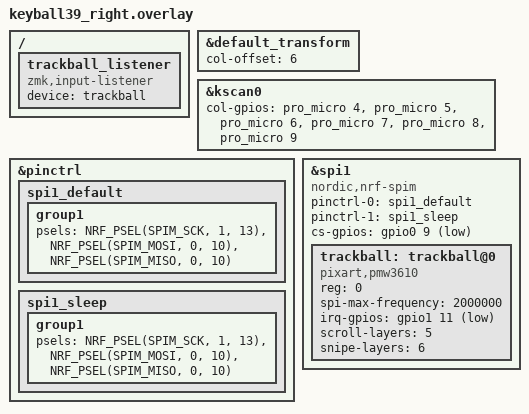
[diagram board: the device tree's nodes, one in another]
/*
 * Copyright (c) 2020 ZMK Contributors
 *
 * SPDX-License-Identifier: MIT
 */

#include "keyball39.dtsi"

&default_transform {
    col-offset = <6>;
};

&kscan0 {
	col-gpios
		= <&pro_micro 4 GPIO_ACTIVE_HIGH>
		, <&pro_micro 5 GPIO_ACTIVE_HIGH>
		, <&pro_micro 6 GPIO_ACTIVE_HIGH>
		, <&pro_micro 7 GPIO_ACTIVE_HIGH>
		, <&pro_micro 8 GPIO_ACTIVE_HIGH>
        , <&pro_micro 9 GPIO_ACTIVE_HIGH>
		;
};

&pinctrl {
    spi1_default: spi1_default {
        group1 {
            psels = <NRF_PSEL(SPIM_SCK, 1, 13)>,
                <NRF_PSEL(SPIM_MOSI, 0, 10)>,
                <NRF_PSEL(SPIM_MISO, 0, 10)>;
        };
    };

    /*
     * Sleep state intentionally mirrors the default state with NO
     * low-power-enable. The PMW3610 uses 3-wire SPI (MOSI/MISO share P0.10);
     * letting the bus pins drop to a low-power config on idle glitches the
     * first transaction after wake, desyncing SPI framing so reads come back
     * byte-shifted (looks like a sudden rotation) or fail (sensor dies).
     * Keeping the pins in their active config across idle avoids that.
     */
    spi1_sleep: spi1_sleep {
        group1 {
            psels = <NRF_PSEL(SPIM_SCK, 1, 13)>,
                <NRF_PSEL(SPIM_MOSI, 0, 10)>,
                <NRF_PSEL(SPIM_MISO, 0, 10)>;
        };
    };
};

&spi1 {
    status = "okay";
    compatible = "nordic,nrf-spim";
    pinctrl-0 = <&spi1_default>;
    pinctrl-1 = <&spi1_sleep>;
    pinctrl-names = "default", "sleep";
    cs-gpios = <&gpio0 9 GPIO_ACTIVE_LOW>;

    trackball: trackball@0 {
        status = "okay";
        compatible = "pixart,pmw3610";
        reg = <0>;
        spi-max-frequency = <2000000>;
        irq-gpios = <&gpio1 11 (GPIO_ACTIVE_LOW | GPIO_PULL_UP)>;
	scroll-layers = <5>;
	snipe-layers = <6>;
    };
};

/ {
  trackball_listener {
    compatible = "zmk,input-listener";
    device = <&trackball>;

  };
};
